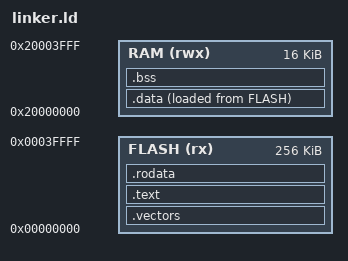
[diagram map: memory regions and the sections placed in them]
ENTRY(_start)

MEMORY
{
    FLASH (rx)  : ORIGIN = 0x00000000, LENGTH = 256K
    RAM   (rwx) : ORIGIN = 0x20000000, LENGTH = 16K
}

SECTIONS
{
    .vectors :
    {
        KEEP(*(.vectors))
    } > FLASH

    .text :
    {
        *(.text*)
    } > FLASH

    .rodata :
    {
        *(.rodata*)
    } > FLASH

    .data :
    {
        __data_start = .;
        *(.data*)
        __data_end = .;
    } > RAM AT > FLASH

    __data_load = LOADADDR(.data);

    .bss :
    {
        __bss_start = .;
        *(.bss*)
        *(COMMON)
        __bss_end = .;
    } > RAM

    /DISCARD/ :
    {
        *(.comment)
        *(.note*)
        *(.eh_frame)
    }
}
